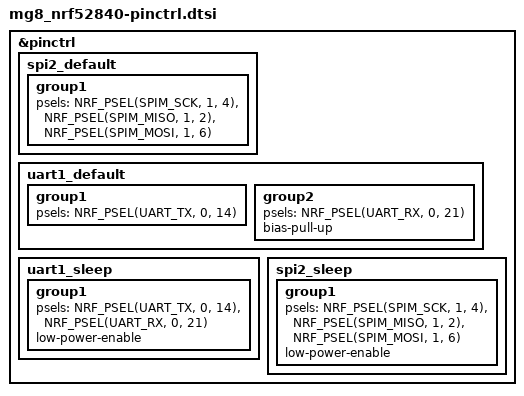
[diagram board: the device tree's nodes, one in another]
/* Minew MG8 pin control */

&pinctrl {
	/* W25Q64JV external flash */
	spi2_default: spi2_default {
		group1 {
			psels = <NRF_PSEL(SPIM_SCK, 1, 4)>,
				<NRF_PSEL(SPIM_MISO, 1, 2)>,
				<NRF_PSEL(SPIM_MOSI, 1, 6)>;
		};
	};

	/*
	 * Modem main UART through the level shifter. RX gets a pull-up so it idles high while the
	 * modem is off (the shifter is disabled then and leaves the line floating).
	 */
	uart1_default: uart1_default {
		group1 {
			psels = <NRF_PSEL(UART_TX, 0, 14)>;
		};
		group2 {
			psels = <NRF_PSEL(UART_RX, 0, 21)>;
			bias-pull-up;
		};
	};

	uart1_sleep: uart1_sleep {
		group1 {
			psels = <NRF_PSEL(UART_TX, 0, 14)>,
				<NRF_PSEL(UART_RX, 0, 21)>;
			low-power-enable;
		};
	};

	spi2_sleep: spi2_sleep {
		group1 {
			psels = <NRF_PSEL(SPIM_SCK, 1, 4)>,
				<NRF_PSEL(SPIM_MISO, 1, 2)>,
				<NRF_PSEL(SPIM_MOSI, 1, 6)>;
			low-power-enable;
		};
	};
};
